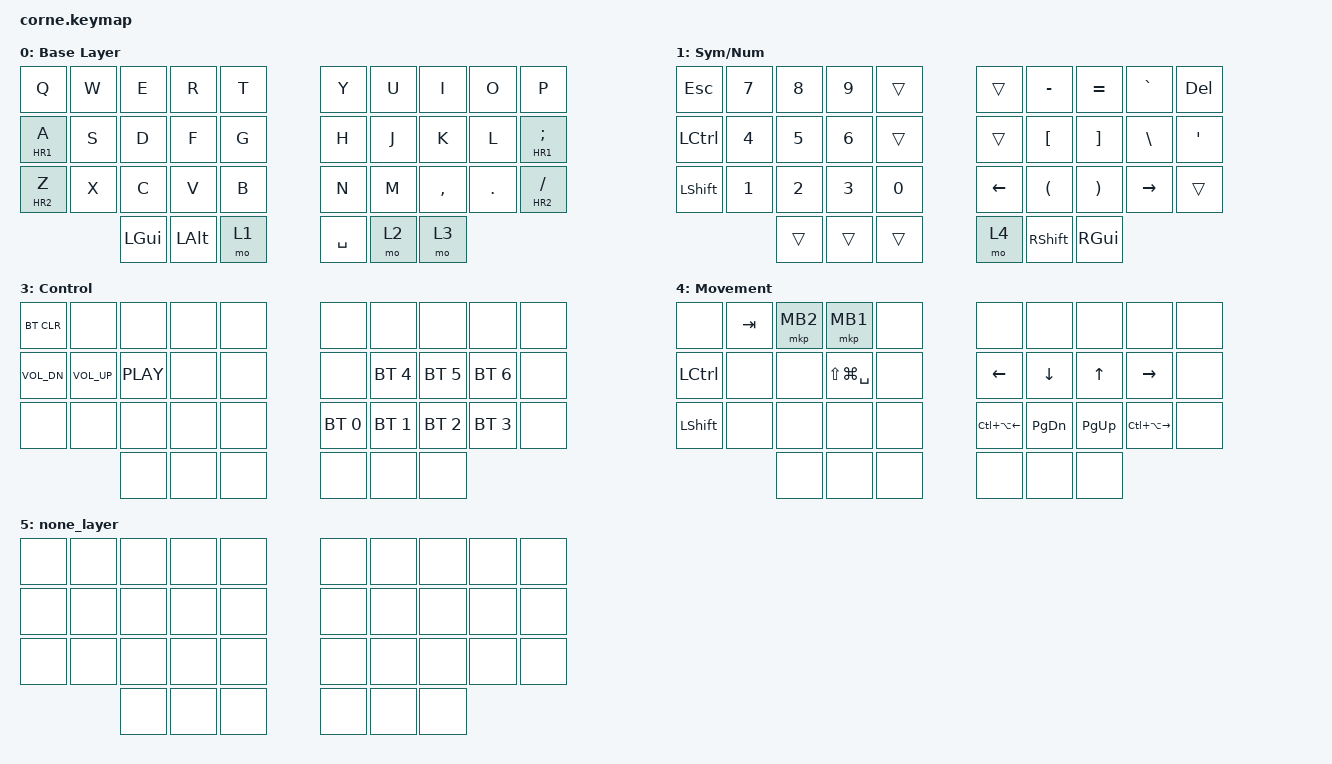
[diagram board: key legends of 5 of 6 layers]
#include <behaviors.dtsi>
#include <dt-bindings/zmk/keys.h>
#include <dt-bindings/zmk/bt.h>
#include <dt-bindings/zmk/mouse.h>

// layers
#define SYSTEM 1
#define BLUETOOTH 2
#define APPS 3
#define SYMBOLS 4
#define NUMBERS 5
#define NUMPAD 6
#define F1_F12 7

// home row
#define HR1 LCTRL
#define HR2 LSHFT
#define HR3 RALT
#define HR4 LCTRL

#define MV_TB_L LC(LS(PG_UP))
#define MV_TB_R LC(LS(PG_DN))
#define PREV_TAB LC(LS(TAB))
#define NEXT_TAB LC(TAB)

#define PREV_SPACE LA(P)
#define NEXT_SPACE LA(N)


#define MAKE_TAP_SHIFT(name, tap, shift) \
    name: name { \
        compatible = "zmk,behavior-mod-morph"; \
        label = #name; \
        #binding-cells = <0>; \
        bindings = <&kp tap>, <&kp shift>; \
        mods = <(MOD_LSFT|MOD_RSFT)>; \
    };


// fixes "system layer not activating" perceived bug
//
// > triggers the hold behavior when the tapping-term-ms has expired or another key is pressed
// > — https://zmk.dev/docs/behaviors/hold-tap#flavors
&lt {
    flavor = "hold-preferred";
};

// fixes "alt instead of apostrophe" bug
&mt {
    flavor = "tap-preferred";
};


/ {
    chosen {
        zmk,matrix_transform = &five_column_transform;
    };

    combos {
        compatible = "zmk,combos";
        combo_esc {
            timeout-ms = <30>;
            key-positions = <1 2>;
            bindings = <&kp ESC>;
        };
        combo_tab {
            timeout-ms = <30>;
            key-positions = <11 12>;
            bindings = <&kp TAB>;
        };
        combo_bksp {
            timeout-ms = <30>;
            key-positions = <7 8>;
            bindings = <&kp BKSP>;
        };
        combo_enter {
            timeout-ms = <30>;
            key-positions = <17 18>;
            bindings = <&kp ENTER>;
        };
    };

    behaviors {
    };

    keymap {
        compatible = "zmk,keymap";
        default_layer {
        label = "Base Layer";
        bindings = <
&kp Q &kp      W &kp      E &kp      R &kp T          &kp Y &kp      U &kp      I &kp      O &kp P
&mt HR1 A &kp  S &kp      D &kp      F &kp G          &kp H &kp      J &kp      K &kp      L &mt HR1 SEMI 
&mt HR2 Z &kp  X &kp      C &kp      V &kp B          &kp N &kp      M &kp  COMMA &kp    DOT &mt HR2 FSLH
                 &kp LGUI  &kp LALT   &mo 1           &kp SPACE  &mo 2   &mo 3 
            >;
        };
        lower_layer {
        label = "Sym/Num";
        bindings = <
                &kp ESC   &kp N7 &kp N8 &kp N9 &trans   &trans &kp MINUS &kp EQUAL  &kp GRAVE  &kp DEL
                &kp LCTRL &kp N4 &kp N5 &kp N6 &trans   &trans &kp LBKT  &kp RBKT   &kp BSLH   &kp SQT
                &kp LSHFT &kp N1 &kp N2 &kp N3 &kp N0   &kp LEFT &kp LPAR  &kp RPAR   &kp RIGHT     &trans
                &trans &trans &trans   &mo 4 &kp RSHFT &kp RGUI
                >;
        };
        nav_layer {
        label = "Nav";
        bindings = <
                &kp LG(Q)     &kp LG(W)    &none &none &none    &none &none &none &none &none
                &kp LCTRL     &kp LA(N4)   &kp LA(N5) &kp LA(N6)   &trans             &kp MV_TB_L &kp PREV_TAB &kp NEXT_TAB &kp MV_TB_R &kp BSLH
                &kp LSHFT     &kp LA(N1)   &kp LA(N2) &kp LA(N3)   &trans             &kp LS(LA(P)) &kp LA(P)  &kp LA(N) &kp LS(LA(N))
                &trans &trans &trans   &trans &trans &trans
                >;
        };

        control_layer {
        label = "Control";
            bindings = <
&bt BT_CLR   &none        &none      &none &none    &none &none &none &none &none
&kp C_VOL_DN &kp C_VOL_UP &kp C_PLAY &none &none    &none &bt BT_SEL 4 &bt BT_SEL 5 &bt BT_SEL 6 &none
&none &none &none &none &none                       &bt BT_SEL 0 &bt BT_SEL 1 &bt BT_SEL 2 &bt BT_SEL 3 &none
            &none &none &none                       &none &none &none
            >;
        };

        movement_layer {
        label = "Movement";
            bindings = <
&none &kp TAB &mkp MB2 &mkp MB1 &none    &none &none &none &none &none
&kp LCTRL &none &none &kp LS(LG(SPACE)) &none    &kp LEFT &kp DOWN &kp UP &kp RIGHT &none
&kp LSHFT &none &none &none &none    &kp LC(LA(LEFT)) &kp PG_DN &kp PG_UP &kp LC(LA(RIGHT)) &none
            &none &none &none    &none &none &none
            >;
        };

        none_layer {
            bindings = <
&none &none &none &none &none    &none &none &none &none &none
&none &none &none &none &none    &none &none &none &none &none
&none &none &none &none &none    &none &none &none &none &none
            &none &none &none    &none &none &none
            >;
        };
    };
};
